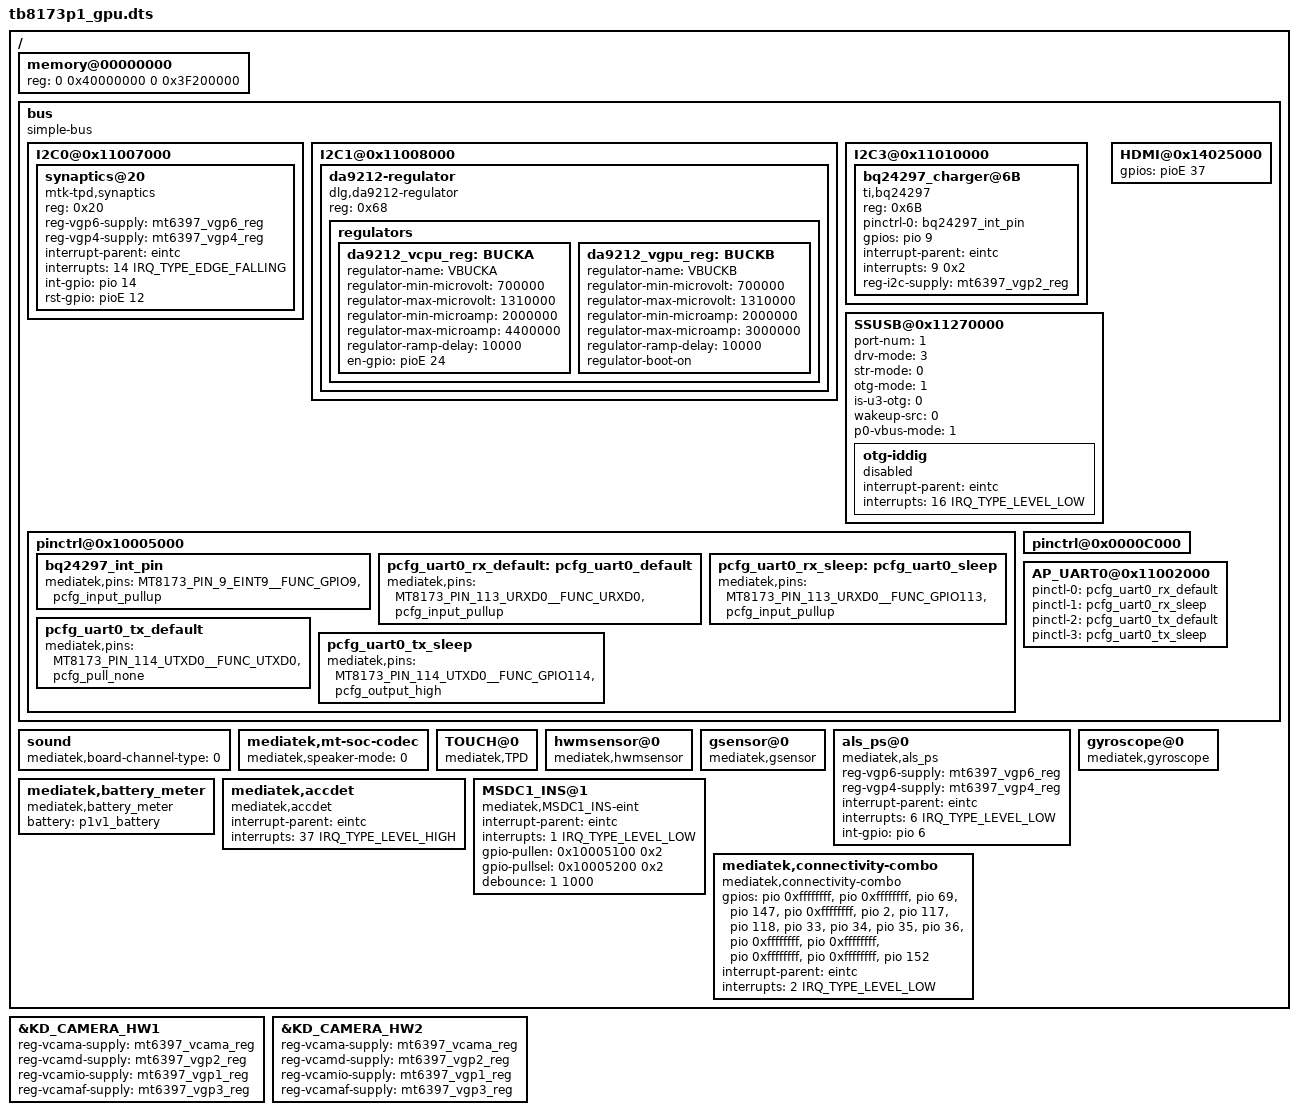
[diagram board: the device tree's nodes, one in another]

/dts-v1/;

#include "mt8173.dtsi"

/ {
  memory@00000000 {
		device_type = "memory";
		reg = <0 0x40000000 0 0x3F200000>;
	};

	bus {
		compatible = "simple-bus";
		#address-cells = <1>;
		#size-cells = <1>;
		ranges = <0 0 0 0xffffffff>;

		I2C0@0x11007000 {
			synaptics@20 {
				compatible = "mtk-tpd,synaptics";
				reg = <0x20>;
				reg-vgp6-supply = <&mt6397_vgp6_reg>;
				reg-vgp4-supply = <&mt6397_vgp4_reg>;
				interrupt-parent = <&eintc>;
				interrupts = <14 IRQ_TYPE_EDGE_FALLING>;
				int-gpio = <&pio 14 0>;
				rst-gpio = <&pioE 12 0>;
			};
		};
		I2C1@0x11008000 {
			da9212-regulator {
				compatible = "dlg,da9212-regulator";
				#address-cells = <0>;
				reg = <0x68>;
				regulators {
					da9212_vcpu_reg: BUCKA {
						regulator-name = "VBUCKA";
						regulator-min-microvolt = < 700000>;
						regulator-max-microvolt = <1310000>;
						regulator-min-microamp 	= <2000000>;
						regulator-max-microamp 	= <4400000>;
						regulator-ramp-delay = <10000>;
						en-gpio = <&pioE 24 0>;
					};
					da9212_vgpu_reg: BUCKB {
						regulator-name = "VBUCKB";
						regulator-min-microvolt = < 700000>;
						regulator-max-microvolt = <1310000>;
						regulator-min-microamp 	= <2000000>;
						regulator-max-microamp 	= <3000000>;
						regulator-ramp-delay = <10000>;
						regulator-boot-on;
					};
				};
			};
		};
		I2C3@0x11010000 {
			bq24297_charger@6B {
				compatible = "ti,bq24297";
				reg = <0x6B>;
				pinctrl-names = "default";
				pinctrl-0 = <&bq24297_int_pin>;
				gpios = <&pio 9 0>;
				interrupt-parent = <&eintc>;
				interrupts = <9 0x2>;
				reg-i2c-supply = <&mt6397_vgp2_reg>;
			};
		};

		SSUSB@0x11270000 {
			port-num = <1>; /* is the max(u2-ports, u3-ports) */
			drv-mode = <3>; /* 1: host, 2: device, 3 dual-mode */
			str-mode = <0>; /* 0: none for tablet, 1: alive for wifi-bt-eth, 2: deep str*/
			otg-mode = <1>; /* 0: srp-hnp, 1: iddig-eint, 2: manual */
			is-u3-otg = <0>; /* device is usb3.0? */
			wakeup-src = <0>; /* bit0: iddig, bit1: linestate-0p, bit2: linestate-1p */
			p0-vbus-mode = <1>; /* 0: default on, 1: by charger ic, 2: gpio */
			otg-iddig {
				interrupt-parent = <&eintc>;
				interrupts = <16 IRQ_TYPE_LEVEL_LOW>; /* init is low-level */
				status = "disabled"; /* don't create platform-device */
			};
		};

		HDMI@0x14025000 {
			gpios = <&pioE 37 0>; /*5V DDC ENABLE GPIO */
		};


		pinctrl@0x10005000 {
			bq24297_int_pin: bq24297_int_pin {
				mediatek,pins = <MT8173_PIN_9_EINT9__FUNC_GPIO9 &pcfg_input_pullup>;
			};
			pcfg_uart0_rx_default: pcfg_uart0_default {
				mediatek,pins = <MT8173_PIN_113_URXD0__FUNC_URXD0 &pcfg_input_pullup>;
			};
			pcfg_uart0_rx_sleep: pcfg_uart0_sleep {
				mediatek,pins = <MT8173_PIN_113_URXD0__FUNC_GPIO113 &pcfg_input_pullup>;
			};
			pcfg_uart0_tx_default: pcfg_uart0_tx_default {
				mediatek,pins = <MT8173_PIN_114_UTXD0__FUNC_UTXD0 &pcfg_pull_none>;
			};
			pcfg_uart0_tx_sleep: pcfg_uart0_tx_sleep {
				mediatek,pins = <MT8173_PIN_114_UTXD0__FUNC_GPIO114 &pcfg_output_high>;
			};
		};

                pinctrl@0x0000C000 {/*External gpio pinctrl*/
                };

		AP_UART0@0x11002000 {
			pinctrl-names = "rx_default", "rx_sleep","tx_default", "tx_sleep";
			pinctl-0 = <&pcfg_uart0_rx_default>;
			pinctl-1 = <&pcfg_uart0_rx_sleep>;
			pinctl-2 = <&pcfg_uart0_tx_default>;
			pinctl-3 = <&pcfg_uart0_tx_sleep>;
		};
	};

	sound {
		mediatek,board-channel-type = <0>; /* 0(Stereo) 1(MonoLeft) 2(MonoRight) */
	};

	mediatek,mt-soc-codec {
		mediatek,speaker-mode = <0>; /* 0(CLASSD) 1(CLASSAB) */
	};

	TOUCH@0 {
		compatible = "mediatek,TPD";
	};
	hwmsensor@0 {
		compatible = "mediatek,hwmsensor";
	};
	gsensor@0 {
		compatible = "mediatek,gsensor";
	};
	als_ps@0 {
		compatible = "mediatek,als_ps";
		reg-vgp6-supply = <&mt6397_vgp6_reg>;
		reg-vgp4-supply = <&mt6397_vgp4_reg>;
		interrupt-parent = <&eintc>;
		interrupts = <6 IRQ_TYPE_LEVEL_LOW>;
		int-gpio = <&pio 6 0>;
	};
	gyroscope@0 {
		compatible = "mediatek,gyroscope";
	};

	mediatek,battery_meter {
		compatible = "mediatek,battery_meter";
		battery = "p1v1_battery";
	};

	mediatek,accdet {
		compatible = "mediatek,accdet";
		interrupt-parent = <&eintc>;
		interrupts = <37 IRQ_TYPE_LEVEL_HIGH>;
	};

	MSDC1_INS@1 {
		compatible = "mediatek,MSDC1_INS-eint";
		interrupt-parent = <&eintc>;
		interrupts = <1 IRQ_TYPE_LEVEL_LOW>;
		gpio-pullen = <0x10005100 0x2>;	/* GPIO1 pull enable(reg-base, mask(1-enable,0-disable)) */
		gpio-pullsel = <0x10005200 0x2>;	/* GPIO1 pull select(reg-base, mask(1-HIGH,0-LOW)) */
		debounce = <1 1000>;
	};

/*
	KPD_PWRKEY-eint@0 {
		compatible = "mediatek,KPD_PWRKEY-eint";
		interrupt-parent = <&eintc>;
		interrupts = <10 IRQ_TYPE_EDGE_FALLING>;
	};

	KPD_SLIDE-eint@0 {
		compatible = "mediatek,KPD_SLIDE-eint";
		interrupt-parent = <&eintc>;
		interrupts = <11 IRQ_TYPE_EDGE_FALLING>;
	};*/

	/* Connectivity */
	mediatek,connectivity-combo {
		compatible = "mediatek,connectivity-combo";
		/* 0) GPIO_COMBO_LDO_EN_PIN
		   1) GPIO_COMBO_PMUV28_EN_PIN
		   2) GPIO_COMBO_PMU_EN_PIN
		   3) GPIO_COMBO_RST_PIN is ext pin on 6397, gpio num is 135+num
		   4) GPIO_COMBO_BGF_EINT_PIN
		   5) GPIO_WIFI_EINT_PIN
		   6) GPIO_COMBO_URXD_PIN
		   7) GPIO_COMBO_UTXD_PIN
		   8) GPIO_PCM_DAICLK_PIN
		   9) GPIO_PCM_DAIPCMIN_PIN
		   10) GPIO_PCM_DAIPCMOUT_PIN
		   11) GPIO_PCM_DAISYNC_PIN
		   12) GPIO_COMBO_I2S_CK_PIN
		   13) GPIO_COMBO_I2S_WS_PIN
		   14) GPIO_COMBO_I2S_DAT_PIN
		   15) GPIO_GPS_SYNC_PIN
		   16) GPIO_GPS_LNA_PIN is ext pin on 6397, gpio num is 135+num */
		gpios = <&pio 0xffffffff 0
				 &pio 0xffffffff 0
				 &pio 69 0
				 &pio 147 0
				 &pio 0xffffffff 0
				 &pio 2 0
				 &pio 117 0
				 &pio 118 0
				 &pio 33 0
				 &pio 34 0
				 &pio 35 0
				 &pio 36 0
				 &pio 0xffffffff 0
				 &pio 0xffffffff 0
				 &pio 0xffffffff 0
				 &pio 0xffffffff 0
				 &pio 152 0>;
		interrupt-parent = <&eintc>;
		/*0 WIFI EINT num is 2 active low level-sensitive
		  1 BGF EINT num is 0xffffffff active low level-sensitive */
		interrupts = < 2 IRQ_TYPE_LEVEL_LOW >;
	};
};

/* Camera Power Regulator Framework */
/* Redefine the camera power pins accroding to project's schematic */
/* Main Cam */
&KD_CAMERA_HW1{
	reg-vcama-supply = <&mt6397_vcama_reg>;		/* AVDD */
	reg-vcamd-supply = <&mt6397_vgp2_reg>;		/* DVDD : not use, it only for i2c#3*/
	reg-vcamio-supply = <&mt6397_vgp1_reg>;		/* DOVDD */
	reg-vcamaf-supply = <&mt6397_vgp3_reg>;		/* AFVDD */
};

/* Sub Cam */
/* FIX ME: same power pins as Main ? */
&KD_CAMERA_HW2{
	reg-vcama-supply = <&mt6397_vcama_reg>;		/* AVDD */
	reg-vcamd-supply = <&mt6397_vgp2_reg>;		/* DVDD : not use, it only for i2c#3*/
	reg-vcamio-supply = <&mt6397_vgp1_reg>;		/* DOVDD */
	reg-vcamaf-supply = <&mt6397_vgp3_reg>;		/* AFVDD */
};
